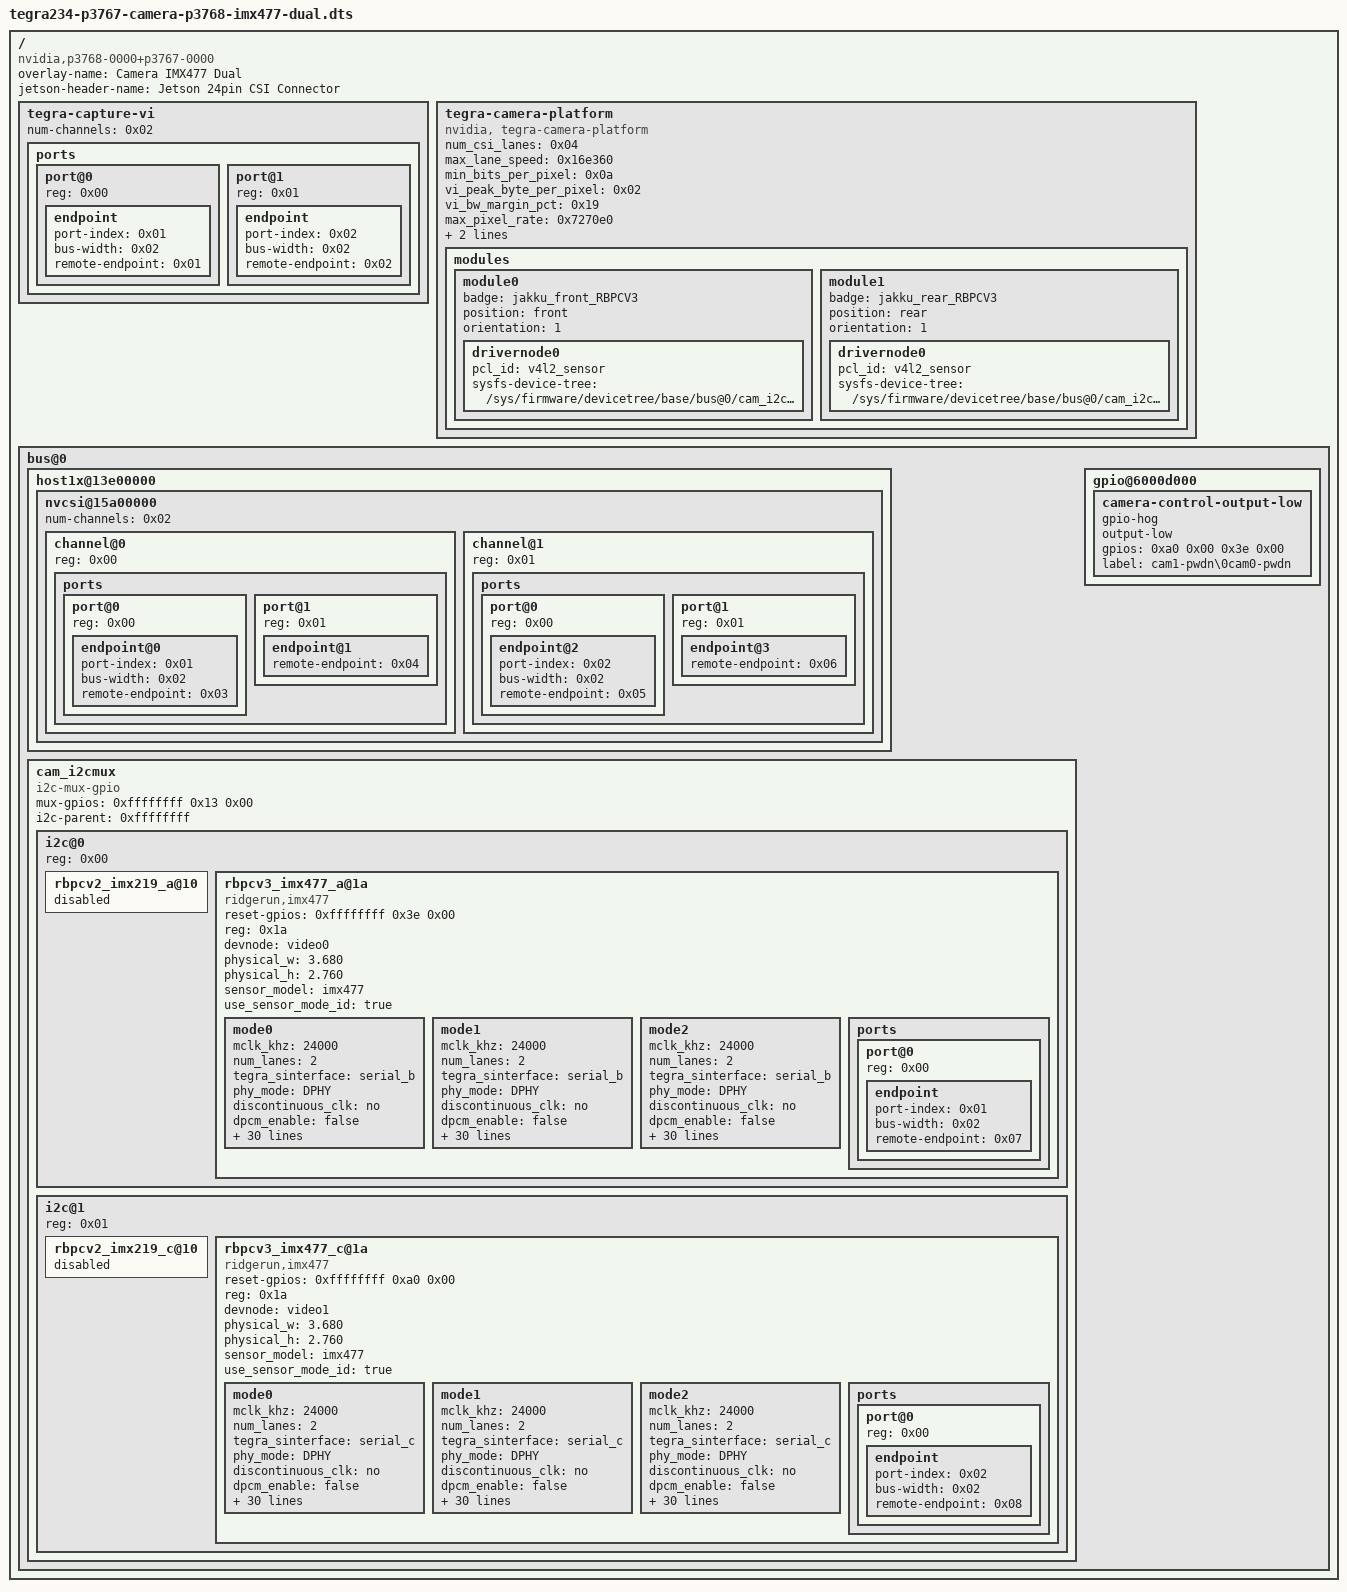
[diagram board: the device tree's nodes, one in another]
/dts-v1/;

/ {
	overlay-name = "Camera IMX477 Dual";
	jetson-header-name = "Jetson 24pin CSI Connector";
	compatible = "nvidia,p3768-0000+p3767-0000\0nvidia,p3768-0000+p3767-0001\0nvidia,p3768-0000+p3767-0003\0nvidia,p3768-0000+p3767-0004\0nvidia,p3768-0000+p3767-0005\0nvidia,p3768-0000+p3767-0000-super\0nvidia,p3768-0000+p3767-0001-super\0nvidia,p3768-0000+p3767-0003-super\0nvidia,p3768-0000+p3767-0004-super\0nvidia,p3768-0000+p3767-0005-super";

	fragment@0 {
		target-path = "/";

		__overlay__ {

			tegra-capture-vi {
				num-channels = <0x02>;

				ports {
					#address-cells = <0x01>;
					#size-cells = <0x00>;

					port@0 {
						reg = <0x00>;

						endpoint {
							port-index = <0x01>;
							bus-width = <0x02>;
							remote-endpoint = <0x01>;
							phandle = <0x04>;
						};
					};

					port@1 {
						reg = <0x01>;

						endpoint {
							port-index = <0x02>;
							bus-width = <0x02>;
							remote-endpoint = <0x02>;
							phandle = <0x06>;
						};
					};
				};
			};

			tegra-camera-platform {
				compatible = "nvidia, tegra-camera-platform";
				num_csi_lanes = <0x04>;
				max_lane_speed = <0x16e360>;
				min_bits_per_pixel = <0x0a>;
				vi_peak_byte_per_pixel = <0x02>;
				vi_bw_margin_pct = <0x19>;
				max_pixel_rate = <0x7270e0>;
				isp_peak_byte_per_pixel = <0x05>;
				isp_bw_margin_pct = <0x19>;

				modules {

					module0 {
						badge = "jakku_front_RBPCV3";
						position = "front";
						orientation = "1";

						drivernode0 {
							pcl_id = "v4l2_sensor";
							sysfs-device-tree = "/sys/firmware/devicetree/base/bus@0/cam_i2cmux/i2c@0/rbpcv3_imx477_a@1a";
						};
					};

					module1 {
						badge = "jakku_rear_RBPCV3";
						position = "rear";
						orientation = "1";

						drivernode0 {
							pcl_id = "v4l2_sensor";
							sysfs-device-tree = "/sys/firmware/devicetree/base/bus@0/cam_i2cmux/i2c@1/rbpcv3_imx477_c@1a";
						};
					};
				};
			};

			bus@0 {

				host1x@13e00000 {

					nvcsi@15a00000 {
						num-channels = <0x02>;
						#address-cells = <0x01>;
						#size-cells = <0x00>;

						channel@0 {
							reg = <0x00>;

							ports {
								#address-cells = <0x01>;
								#size-cells = <0x00>;

								port@0 {
									reg = <0x00>;

									endpoint@0 {
										port-index = <0x01>;
										bus-width = <0x02>;
										remote-endpoint = <0x03>;
										phandle = <0x07>;
									};
								};

								port@1 {
									reg = <0x01>;

									endpoint@1 {
										remote-endpoint = <0x04>;
										phandle = <0x01>;
									};
								};
							};
						};

						channel@1 {
							reg = <0x01>;

							ports {
								#address-cells = <0x01>;
								#size-cells = <0x00>;

								port@0 {
									reg = <0x00>;

									endpoint@2 {
										port-index = <0x02>;
										bus-width = <0x02>;
										remote-endpoint = <0x05>;
										phandle = <0x08>;
									};
								};

								port@1 {
									reg = <0x01>;

									endpoint@3 {
										remote-endpoint = <0x06>;
										phandle = <0x02>;
									};
								};
							};
						};
					};
				};

				cam_i2cmux {
					status = "okay";
					compatible = "i2c-mux-gpio";
					#address-cells = <0x01>;
					#size-cells = <0x00>;
					mux-gpios = <0xffffffff 0x13 0x00>;
					i2c-parent = <0xffffffff>;

					i2c@0 {
						status = "okay";
						reg = <0x00>;
						#address-cells = <0x01>;
						#size-cells = <0x00>;

						rbpcv2_imx219_a@10 {
							status = "disabled";
						};

						rbpcv3_imx477_a@1a {
							reset-gpios = <0xffffffff 0x3e 0x00>;
							compatible = "ridgerun,imx477";
							reg = <0x1a>;
							devnode = "video0";
							physical_w = "3.680";
							physical_h = "2.760";
							sensor_model = "imx477";
							use_sensor_mode_id = "true";

							mode0 {
								mclk_khz = "24000";
								num_lanes = "2";
								tegra_sinterface = "serial_b";
								phy_mode = "DPHY";
								discontinuous_clk = "no";
								dpcm_enable = "false";
								cil_settletime = "0";
								lane_polarity = "6";
								active_w = "4032";
								active_h = "3040";
								mode_type = "bayer";
								pixel_phase = "rggb";
								csi_pixel_bit_depth = "10";
								readout_orientation = "90";
								line_length = "9024\0";
								inherent_gain = "1";
								mclk_multiplier = "80";
								pix_clk_hz = "840000000";
								gain_factor = "16";
								framerate_factor = "1000000";
								exposure_factor = "1000000";
								min_gain_val = "16";
								max_gain_val = "356";
								step_gain_val = "1";
								default_gain = "16";
								min_hdr_ratio = "1";
								max_hdr_ratio = "1";
								min_framerate = "2000000";
								max_framerate = "30000000";
								step_framerate = "1";
								default_framerate = "30000000";
								min_exp_time = "13";
								max_exp_time = "683709";
								step_exp_time = "1";
								default_exp_time = "2495";
								embedded_metadata_height = "2";
							};

							mode1 {
								mclk_khz = "24000";
								num_lanes = "2";
								tegra_sinterface = "serial_b";
								phy_mode = "DPHY";
								discontinuous_clk = "no";
								dpcm_enable = "false";
								cil_settletime = "0";
								lane_polarity = "6";
								active_w = "3840";
								active_h = "2160";
								mode_type = "bayer";
								pixel_phase = "rggb";
								csi_pixel_bit_depth = "10";
								readout_orientation = "90";
								line_length = "11200";
								inherent_gain = "1";
								mclk_multiplier = "80";
								pix_clk_hz = "300000000";
								gain_factor = "16";
								framerate_factor = "1000000";
								exposure_factor = "1000000";
								min_gain_val = "16";
								max_gain_val = "356";
								step_gain_val = "1";
								default_gain = "16";
								min_hdr_ratio = "1";
								max_hdr_ratio = "1";
								min_framerate = "2000000";
								max_framerate = "30000000";
								step_framerate = "1";
								default_framerate = "30000000";
								min_exp_time = "13";
								max_exp_time = "683709";
								step_exp_time = "1";
								default_exp_time = "2495";
								embedded_metadata_height = "2";
							};

							mode2 {
								mclk_khz = "24000";
								num_lanes = "2";
								tegra_sinterface = "serial_b";
								phy_mode = "DPHY";
								discontinuous_clk = "no";
								dpcm_enable = "false";
								cil_settletime = "0";
								lane_polarity = "6";
								active_w = "1920";
								active_h = "1080";
								mode_type = "bayer";
								pixel_phase = "rggb";
								csi_pixel_bit_depth = "10";
								readout_orientation = "90";
								line_length = "7000";
								inherent_gain = "1";
								mclk_multiplier = "80";
								pix_clk_hz = "300000000";
								gain_factor = "16";
								framerate_factor = "1000000";
								exposure_factor = "1000000";
								min_gain_val = "16";
								max_gain_val = "356";
								step_gain_val = "1";
								default_gain = "16";
								min_hdr_ratio = "1";
								max_hdr_ratio = "1";
								min_framerate = "2000000";
								max_framerate = "60000000";
								step_framerate = "1";
								default_framerate = "60000000";
								min_exp_time = "13";
								max_exp_time = "683709";
								step_exp_time = "1";
								default_exp_time = "2495";
								embedded_metadata_height = "2";
							};

							ports {
								#address-cells = <0x01>;
								#size-cells = <0x00>;

								port@0 {
									reg = <0x00>;

									endpoint {
										status = "okay";
										port-index = <0x01>;
										bus-width = <0x02>;
										remote-endpoint = <0x07>;
										phandle = <0x03>;
									};
								};
							};
						};
					};

					i2c@1 {
						status = "okay";
						reg = <0x01>;
						#address-cells = <0x01>;
						#size-cells = <0x00>;

						rbpcv2_imx219_c@10 {
							status = "disabled";
						};

						rbpcv3_imx477_c@1a {
							reset-gpios = <0xffffffff 0xa0 0x00>;
							compatible = "ridgerun,imx477";
							reg = <0x1a>;
							devnode = "video1";
							physical_w = "3.680";
							physical_h = "2.760";
							sensor_model = "imx477";
							use_sensor_mode_id = "true";

							mode0 {
								mclk_khz = "24000";
								num_lanes = "2";
								tegra_sinterface = "serial_c";
								phy_mode = "DPHY";
								discontinuous_clk = "no";
								dpcm_enable = "false";
								cil_settletime = "0";
								lane_polarity = "0";
								active_w = "4032";
								active_h = "3040";
								mode_type = "bayer";
								pixel_phase = "rggb";
								csi_pixel_bit_depth = "10";
								readout_orientation = "90";
								line_length = "9024\0";
								inherent_gain = "1";
								mclk_multiplier = "80";
								pix_clk_hz = "840000000";
								gain_factor = "16";
								framerate_factor = "1000000";
								exposure_factor = "1000000";
								min_gain_val = "16";
								max_gain_val = "356";
								step_gain_val = "1";
								default_gain = "16";
								min_hdr_ratio = "1";
								max_hdr_ratio = "1";
								min_framerate = "2000000";
								max_framerate = "30000000";
								step_framerate = "1";
								default_framerate = "30000000";
								min_exp_time = "13";
								max_exp_time = "683709";
								step_exp_time = "1";
								default_exp_time = "2495";
								embedded_metadata_height = "2";
							};

							mode1 {
								mclk_khz = "24000";
								num_lanes = "2";
								tegra_sinterface = "serial_c";
								phy_mode = "DPHY";
								discontinuous_clk = "no";
								dpcm_enable = "false";
								cil_settletime = "0";
								lane_polarity = "0";
								active_w = "3840";
								active_h = "2160";
								mode_type = "bayer";
								pixel_phase = "rggb";
								csi_pixel_bit_depth = "10";
								readout_orientation = "90";
								line_length = "11200";
								inherent_gain = "1";
								mclk_multiplier = "80";
								pix_clk_hz = "300000000";
								gain_factor = "16";
								framerate_factor = "1000000";
								exposure_factor = "1000000";
								min_gain_val = "16";
								max_gain_val = "356";
								step_gain_val = "1";
								default_gain = "16";
								min_hdr_ratio = "1";
								max_hdr_ratio = "1";
								min_framerate = "2000000";
								max_framerate = "30000000";
								step_framerate = "1";
								default_framerate = "30000000";
								min_exp_time = "13";
								max_exp_time = "683709";
								step_exp_time = "1";
								default_exp_time = "2495";
								embedded_metadata_height = "2";
							};

							mode2 {
								mclk_khz = "24000";
								num_lanes = "2";
								tegra_sinterface = "serial_c";
								phy_mode = "DPHY";
								discontinuous_clk = "no";
								dpcm_enable = "false";
								cil_settletime = "0";
								lane_polarity = "0";
								active_w = "1920";
								active_h = "1080";
								mode_type = "bayer";
								pixel_phase = "rggb";
								csi_pixel_bit_depth = "10";
								readout_orientation = "90";
								line_length = "7000";
								inherent_gain = "1";
								mclk_multiplier = "80";
								pix_clk_hz = "300000000";
								gain_factor = "16";
								framerate_factor = "1000000";
								exposure_factor = "1000000";
								min_gain_val = "16";
								max_gain_val = "356";
								step_gain_val = "1";
								default_gain = "16";
								min_hdr_ratio = "1";
								max_hdr_ratio = "1";
								min_framerate = "2000000";
								max_framerate = "60000000";
								step_framerate = "1";
								default_framerate = "60000000";
								min_exp_time = "13";
								max_exp_time = "683709";
								step_exp_time = "1";
								default_exp_time = "2495";
								embedded_metadata_height = "2";
							};

							ports {
								#address-cells = <0x01>;
								#size-cells = <0x00>;

								port@0 {
									reg = <0x00>;

									endpoint {
										status = "okay";
										port-index = <0x02>;
										bus-width = <0x02>;
										remote-endpoint = <0x08>;
										phandle = <0x05>;
									};
								};
							};
						};
					};
				};

				gpio@6000d000 {

					camera-control-output-low {
						gpio-hog;
						output-low;
						gpios = <0xa0 0x00 0x3e 0x00>;
						label = "cam1-pwdn\0cam0-pwdn";
					};
				};
			};
		};
	};

	__symbols__ {
		rbpcv3_imx477_vi_in0 = "/fragment@0/__overlay__/tegra-capture-vi/ports/port@0/endpoint";
		rbpcv3_imx477_vi_in1 = "/fragment@0/__overlay__/tegra-capture-vi/ports/port@1/endpoint";
		rbpcv3_imx477_csi_in0 = "/fragment@0/__overlay__/bus@0/host1x@13e00000/nvcsi@15a00000/channel@0/ports/port@0/endpoint@0";
		rbpcv3_imx477_csi_out0 = "/fragment@0/__overlay__/bus@0/host1x@13e00000/nvcsi@15a00000/channel@0/ports/port@1/endpoint@1";
		rbpcv3_imx477_csi_in1 = "/fragment@0/__overlay__/bus@0/host1x@13e00000/nvcsi@15a00000/channel@1/ports/port@0/endpoint@2";
		rbpcv3_imx477_csi_out1 = "/fragment@0/__overlay__/bus@0/host1x@13e00000/nvcsi@15a00000/channel@1/ports/port@1/endpoint@3";
		rbpcv3_imx477_out0 = "/fragment@0/__overlay__/bus@0/cam_i2cmux/i2c@0/rbpcv3_imx477_a@1a/ports/port@0/endpoint";
		rbpcv3_imx477_out1 = "/fragment@0/__overlay__/bus@0/cam_i2cmux/i2c@1/rbpcv3_imx477_c@1a/ports/port@0/endpoint";
	};

	__fixups__ {
		gpio_aon = "/fragment@0/__overlay__/bus@0/cam_i2cmux:mux-gpios:0";
		cam_i2c = "/fragment@0/__overlay__/bus@0/cam_i2cmux:i2c-parent:0";
		gpio = "/fragment@0/__overlay__/bus@0/cam_i2cmux/i2c@0/rbpcv3_imx477_a@1a:reset-gpios:0\0/fragment@0/__overlay__/bus@0/cam_i2cmux/i2c@1/rbpcv3_imx477_c@1a:reset-gpios:0";
	};

	__local_fixups__ {

		fragment@0 {

			__overlay__ {

				tegra-capture-vi {

					ports {

						port@0 {

							endpoint {
								remote-endpoint = <0x00>;
							};
						};

						port@1 {

							endpoint {
								remote-endpoint = <0x00>;
							};
						};
					};
				};

				bus@0 {

					host1x@13e00000 {

						nvcsi@15a00000 {

							channel@0 {

								ports {

									port@0 {

										endpoint@0 {
											remote-endpoint = <0x00>;
										};
									};

									port@1 {

										endpoint@1 {
											remote-endpoint = <0x00>;
										};
									};
								};
							};

							channel@1 {

								ports {

									port@0 {

										endpoint@2 {
											remote-endpoint = <0x00>;
										};
									};

									port@1 {

										endpoint@3 {
											remote-endpoint = <0x00>;
										};
									};
								};
							};
						};
					};

					cam_i2cmux {

						i2c@0 {

							rbpcv3_imx477_a@1a {

								ports {

									port@0 {

										endpoint {
											remote-endpoint = <0x00>;
										};
									};
								};
							};
						};

						i2c@1 {

							rbpcv3_imx477_c@1a {

								ports {

									port@0 {

										endpoint {
											remote-endpoint = <0x00>;
										};
									};
								};
							};
						};
					};
				};
			};
		};
	};
};
